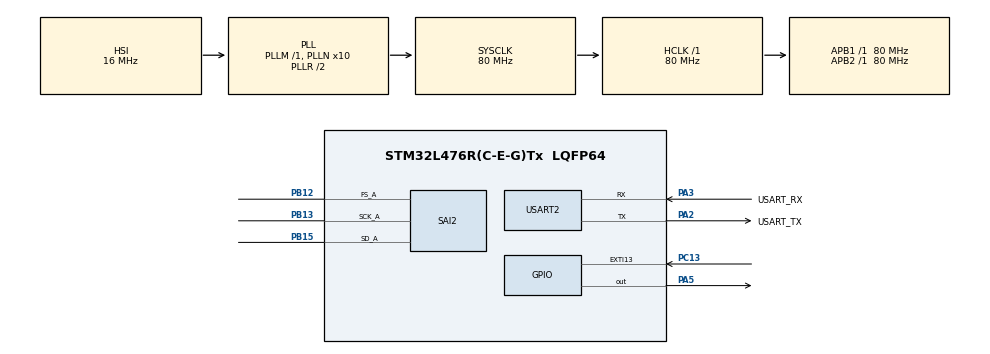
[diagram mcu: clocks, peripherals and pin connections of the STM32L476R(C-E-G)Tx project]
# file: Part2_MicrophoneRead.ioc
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FREERTOS.Tasks01=MicRead,24,128,StartMicRead,Default,NULL,Dynamic,NULL,NULL
Mcu.Family=STM32L4
Mcu.Name=STM32L476R(C-E-G)Tx
Mcu.Package=LQFP64
NUCLEO-L476RG.BUTTON=1
NUCLEO-L476RG.LD2=true
NVIC.EXTI15_10_IRQn=true\:5\:0\:false\:false\:true\:true\:false\:true\:true
NVIC.PriorityGroup=NVIC_PRIORITYGROUP_4
NVIC.TIM6_DAC_IRQn=true\:15\:0\:false\:false\:true\:false\:false\:true\:true
NVIC.TimeBase=TIM6_DAC_IRQn
NVIC.TimeBaseIP=TIM6
PA13\ (JTMS-SWDIO).GPIO_Label=TMS
PA13\ (JTMS-SWDIO).Signal=SYS_JTMS-SWDIO
PA14\ (JTCK-SWCLK).GPIO_Label=TCK
PA14\ (JTCK-SWCLK).Signal=SYS_JTCK-SWCLK
PA2.GPIO_Label=USART_TX
PA2.GPIO_Mode=GPIO_MODE_AF_PP
PA2.GPIO_PuPd=GPIO_NOPULL
PA2.GPIO_Speed=GPIO_SPEED_FREQ_VERY_HIGH
PA2.Mode=Asynchronous
PA2.Signal=USART2_TX
PA3.GPIO_Label=USART_RX
PA3.GPIO_Mode=GPIO_MODE_AF_PP
PA3.GPIO_PuPd=GPIO_NOPULL
PA3.GPIO_Speed=GPIO_SPEED_FREQ_VERY_HIGH
PA3.Mode=Asynchronous
PA3.Signal=USART2_RX
PA5.Signal=GPIO_Output
PB12.Mode=SAI_A_Master
PB12.Signal=SAI2_FS_A
PB13.Mode=SAI_A_Master
PB13.Signal=SAI2_SCK_A
PB15.GPIO_PuPd=GPIO_PULLDOWN
PB15.Mode=SAI_A_Master
PB15.Signal=SAI2_SD_A
PB3\ (JTDO-TRACESWO).GPIO_Label=SWO
PB3\ (JTDO-TRACESWO).Signal=SYS_JTDO-SWO
PC13.Signal=GPXTI13
PC14-OSC32_IN\ (PC14).Signal=RCC_OSC32_IN
PC15-OSC32_OUT\ (PC15).Signal=RCC_OSC32_OUT
PH0-OSC_IN\ (PH0).Signal=RCC_OSC_IN
PH1-OSC_OUT\ (PH1).Signal=RCC_OSC_OUT
ProjectManager.HeapSize=0x200
ProjectManager.StackSize=0x400
ProjectManager.TargetToolchain=CMake
RCC.ADCFreq_Value=64000000
RCC.AHBFreq_Value=80000000
RCC.APB1Freq_Value=80000000
RCC.APB1TimFreq_Value=80000000
RCC.APB2Freq_Value=80000000
RCC.APB2TimFreq_Value=80000000
RCC.CortexFreq_Value=80000000
RCC.HCLKFreq_Value=80000000
RCC.HSE_VALUE=8000000
RCC.HSI_VALUE=16000000
RCC.LSE_VALUE=32768
RCC.MSI_VALUE=4000000
RCC.PLLN=10
RCC.PLLSourceVirtual=RCC_PLLSOURCE_HSI
RCC.PREFETCH_ENABLE=1
RCC.SAI2CLockSelection=RCC_SAI2CLKSOURCE_PLL
RCC.SYSCLKFreq_VALUE=80000000
RCC.SYSCLKSource=RCC_SYSCLKSOURCE_PLLCLK
RCC.USBFreq_Value=64000000
RCC.VCOOutputFreq_Value=160000000
SAI2.AudioFrequency-SAI_A_Master=SAI_AUDIO_FREQUENCY_44K
SAI2.AudioMode-SAI_A_Master=SAI_MODEMASTER_RX
SAI2.BasicDataSize-SAI_A_Master=SAI_PROTOCOL_DATASIZE_24BIT
SAI2.ErrorAudioFreq-SAI_A_Master=1.22 %
SAI2.InitProtocol-SAI_A_Master=Enable
SAI2.Instance-SAI_A_Master=SAI$Index_Block_A
SAI2.MClockEnable-SAI_A_Master=SAI_MASTERCLOCK_DISABLE
SAI2.MonoStereoMode-SAI_A_Master=SAI_STEREOMODE
SAI2.NoDivider-SAI_A_Master=SAI_MASTERDIVIDER_ENABLE
SAI2.OutputDrive-SAI_A_Master=SAI_OUTPUTDRIVE_ENABLE
SAI2.RealAudioFreq-SAI_A_Master=44.642 KHz
SAI2.VirtualMode-SAI_A_Master=VM_MASTER
SAI2.VirtualProtocol-SAI_A_BASIC=VM_BASIC_PROTOCOL
USART2.VirtualMode-Asynchronous=VM_ASYNC
VP_FREERTOS_VS_CMSIS_V2.Mode=CMSIS_V2
VP_NUCLEO-L476RG_VS_BSP_COMMON.Mode=COMMON
VP_SAI2_VP_$IpInstance_SAIA_SAI_BASIC.Mode=SAI_A_BASIC
VP_SYS_VS_tim6.Mode=TIM6
board=NUCLEO-L476RG

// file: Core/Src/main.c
/* USER CODE BEGIN Header */
/**
  ******************************************************************************
  * @file           : main.c
  * @brief          : Main program body
  ******************************************************************************
  * @attention
  *
  * Copyright (c) 2026 STMicroelectronics.
  * All rights reserved.
  *
  * This software is licensed under terms that can be found in the LICENSE file
  * in the root directory of this software component.
  * If no LICENSE file comes with this software, it is provided AS-IS.
  *
  ******************************************************************************
  */
/* USER CODE END Header */
#include "main.h"
#include "cmsis_os.h"

SAI_HandleTypeDef hsai_BlockA2;

UART_HandleTypeDef huart2;

/* Definitions for MicRead */
osThreadId_t MicReadHandle;
const osThreadAttr_t MicRead_attributes = {
  .name = "MicRead",
  .stack_size = 128 * 4,
  .priority = (osPriority_t) osPriorityNormal,
};

void SystemClock_Config(void);
static void MX_GPIO_Init(void);
static void MX_SAI2_Init(void);
static void MX_USART2_UART_Init(void);
void StartMicRead(void *argument);

int main(void)
{

  /* MCU Configuration--------------------------------------------------------*/

  /* Reset of all peripherals, Initializes the Flash interface and the Systick. */
  HAL_Init();

  /* Configure the system clock */
  SystemClock_Config();

  /* Initialize all configured peripherals */
  MX_GPIO_Init();
  MX_SAI2_Init();
  MX_USART2_UART_Init();

  /* Init scheduler */
  osKernelInitialize();

  /* Create the thread(s) */
  /* creation of MicRead */
  MicReadHandle = osThreadNew(StartMicRead, NULL, &MicRead_attributes);

  /* Initialize leds */
  BSP_LED_Init(LED_GREEN);

  /* Initialize USER push-button, will be used to trigger an interrupt each time it's pressed.*/
  BSP_PB_Init(BUTTON_USER, BUTTON_MODE_EXTI);

  /* Start scheduler */
  osKernelStart();

  /* We should never get here as control is now taken by the scheduler */

  /* Infinite loop */
  while (1)
  {

  }
}

void SystemClock_Config(void)
{
  RCC_OscInitTypeDef RCC_OscInitStruct = {0};
  RCC_ClkInitTypeDef RCC_ClkInitStruct = {0};

  /** Configure the main internal regulator output voltage
  */
  if (HAL_PWREx_ControlVoltageScaling(PWR_REGULATOR_VOLTAGE_SCALE1) != HAL_OK)
  {
    Error_Handler();
  }

  /** Initializes the RCC Oscillators according to the specified parameters
  * in the RCC_OscInitTypeDef structure.
  */
  RCC_OscInitStruct.OscillatorType = RCC_OSCILLATORTYPE_HSI;
  RCC_OscInitStruct.HSIState = RCC_HSI_ON;
  RCC_OscInitStruct.HSICalibrationValue = RCC_HSICALIBRATION_DEFAULT;
  RCC_OscInitStruct.PLL.PLLState = RCC_PLL_ON;
  RCC_OscInitStruct.PLL.PLLSource = RCC_PLLSOURCE_HSI;
  RCC_OscInitStruct.PLL.PLLM = 1;
  RCC_OscInitStruct.PLL.PLLN = 10;
  RCC_OscInitStruct.PLL.PLLP = RCC_PLLP_DIV7;
  RCC_OscInitStruct.PLL.PLLQ = RCC_PLLQ_DIV2;
  RCC_OscInitStruct.PLL.PLLR = RCC_PLLR_DIV2;
  if (HAL_RCC_OscConfig(&RCC_OscInitStruct) != HAL_OK)
  {
    Error_Handler();
  }

  /** Initializes the CPU, AHB and APB buses clocks
  */
  RCC_ClkInitStruct.ClockType = RCC_CLOCKTYPE_HCLK|RCC_CLOCKTYPE_SYSCLK
                              |RCC_CLOCKTYPE_PCLK1|RCC_CLOCKTYPE_PCLK2;
  RCC_ClkInitStruct.SYSCLKSource = RCC_SYSCLKSOURCE_PLLCLK;
  RCC_ClkInitStruct.AHBCLKDivider = RCC_SYSCLK_DIV1;
  RCC_ClkInitStruct.APB1CLKDivider = RCC_HCLK_DIV1;
  RCC_ClkInitStruct.APB2CLKDivider = RCC_HCLK_DIV1;

  if (HAL_RCC_ClockConfig(&RCC_ClkInitStruct, FLASH_LATENCY_4) != HAL_OK)
  {
    Error_Handler();
  }
}

static void MX_SAI2_Init(void)
{

  hsai_BlockA2.Instance = SAI2_Block_A;
  hsai_BlockA2.Init.AudioMode = SAI_MODEMASTER_RX;
  hsai_BlockA2.Init.Synchro = SAI_ASYNCHRONOUS;
  hsai_BlockA2.Init.OutputDrive = SAI_OUTPUTDRIVE_ENABLE;
  hsai_BlockA2.Init.NoDivider = SAI_MASTERDIVIDER_ENABLE;
  hsai_BlockA2.Init.FIFOThreshold = SAI_FIFOTHRESHOLD_EMPTY;
  hsai_BlockA2.Init.AudioFrequency = SAI_AUDIO_FREQUENCY_8K;
  hsai_BlockA2.Init.SynchroExt = SAI_SYNCEXT_DISABLE;
  hsai_BlockA2.Init.MonoStereoMode = SAI_STEREOMODE;
  hsai_BlockA2.Init.CompandingMode = SAI_NOCOMPANDING;
  if (HAL_SAI_InitProtocol(&hsai_BlockA2, SAI_I2S_STANDARD, SAI_PROTOCOL_DATASIZE_24BIT, 2) != HAL_OK)
  {
    Error_Handler();
  }

}

static void MX_USART2_UART_Init(void)
{

  huart2.Instance = USART2;
  huart2.Init.BaudRate = 115200;
  huart2.Init.WordLength = UART_WORDLENGTH_8B;
  huart2.Init.StopBits = UART_STOPBITS_1;
  huart2.Init.Parity = UART_PARITY_NONE;
  huart2.Init.Mode = UART_MODE_TX_RX;
  huart2.Init.HwFlowCtl = UART_HWCONTROL_NONE;
  huart2.Init.OverSampling = UART_OVERSAMPLING_16;
  huart2.Init.OneBitSampling = UART_ONE_BIT_SAMPLE_DISABLE;
  huart2.AdvancedInit.AdvFeatureInit = UART_ADVFEATURE_NO_INIT;
  if (HAL_UART_Init(&huart2) != HAL_OK)
  {
    Error_Handler();
  }

}

static void MX_GPIO_Init(void)
{

  /* GPIO Ports Clock Enable */
  __HAL_RCC_GPIOC_CLK_ENABLE();
  __HAL_RCC_GPIOH_CLK_ENABLE();
  __HAL_RCC_GPIOA_CLK_ENABLE();
  __HAL_RCC_GPIOB_CLK_ENABLE();

}

void StartMicRead(void *argument)
{
  /* USER CODE BEGIN 5 */
  /* Infinite loop */
  uint32_t buf[16];
  for(;;)
  {
    HAL_SAI_Receive(&hsai_BlockA2, (uint8_t *)buf, 16, HAL_MAX_DELAY);
    osDelay(450);
  }
  /* USER CODE END 5 */
}

void HAL_TIM_PeriodElapsedCallback(TIM_HandleTypeDef *htim)
{
  if (htim->Instance == TIM6)
  {
    HAL_IncTick();
  }
}

void Error_Handler(void)
{
  __disable_irq();
  while (1)
  {
  }
}
